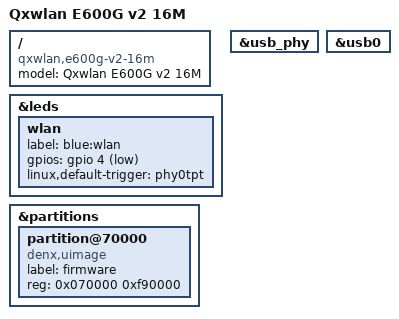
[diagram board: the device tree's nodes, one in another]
// SPDX-License-Identifier: GPL-2.0-or-later OR MIT

#include "qca9531_qxwlan_e600g.dtsi"

/ {
	model = "Qxwlan E600G v2 16M";
	compatible = "qxwlan,e600g-v2-16m", "qca,qca9531";
};

&leds {
	wlan {
		label = "blue:wlan";
		gpios = <&gpio 4 GPIO_ACTIVE_LOW>;
		linux,default-trigger = "phy0tpt";
	};
};

&partitions {
	partition@70000 {
		compatible = "denx,uimage";
		label = "firmware";
		reg = <0x070000 0xf90000>;
	};
};

&usb_phy {
	status = "okay";
};

&usb0 {
	status = "okay";
};
